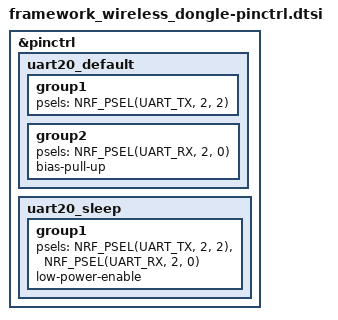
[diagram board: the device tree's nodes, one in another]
/*
 * Copyright (c) 2026 Framework Computer Inc
 * SPDX-License-Identifier: Apache-2.0
 */

&pinctrl {
	uart20_default: uart20_default {
		group1 {
			psels = <NRF_PSEL(UART_TX, 2, 2)>;
		};

		group2 {
			psels = <NRF_PSEL(UART_RX, 2, 0)>;
			bias-pull-up;
		};
	};

	uart20_sleep: uart20_sleep {
		group1 {
			psels = <NRF_PSEL(UART_TX, 2, 2)>,
				<NRF_PSEL(UART_RX, 2, 0)>;
			low-power-enable;
		};
	};
};
